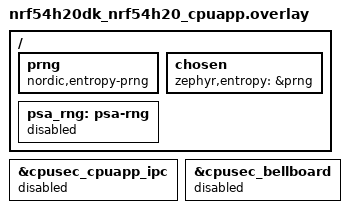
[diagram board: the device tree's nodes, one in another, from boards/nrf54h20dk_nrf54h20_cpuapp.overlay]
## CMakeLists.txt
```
#
# Copyright (c) 2022 Nordic Semiconductor ASA
#
# SPDX-License-Identifier: LicenseRef-Nordic-5-Clause
#

cmake_minimum_required(VERSION 3.20.0)

find_package(Zephyr REQUIRED HINTS $ENV{ZEPHYR_BASE})
project(nrf_wifi_shell)

if(CONFIG_NRF71_WIFI_TX_INJECTION_SUPPORT OR CONFIG_NRF71_WIFI_PROMISCUOUS_SUPPORT)
  target_include_directories(app PUBLIC ${ZEPHYR_BASE}/subsys/net/ip)
endif()

target_sources_ifdef(CONFIG_NRF70_RAW_DATA_TX app PRIVATE src/wifi_raw_tx_pkt_shell.c)
target_sources_ifdef(CONFIG_NRF71_WIFI_TX_INJECTION_SUPPORT app PRIVATE src/wifi_raw_tx_pkt_shell.c)

target_sources_ifdef(CONFIG_NRF70_PROMISC_DATA_RX app PRIVATE src/wifi_promiscuous_shell.c)
target_sources_ifdef(CONFIG_NRF71_WIFI_PROMISCUOUS_SUPPORT app PRIVATE src/wifi_promiscuous_shell.c)

target_sources(app PRIVATE src/main.c)
```

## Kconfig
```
#
# Copyright (c) 2024 Nordic Semiconductor
#
# SPDX-License-Identifier: LicenseRef-Nordic-5-Clause
#

menu "Nordic Shell sample"

if NET_BUF_FIXED_DATA_SIZE

config NET_BUF_DATA_SIZE
	default 1100

endif

# Configure variable network buffer pool sizes for TX and RX
if NET_BUF_VARIABLE_DATA_SIZE

# nRF52 and nRF54 Series targets have less memory
# so smaller pool sizes are recommended for these targets.
config NET_PKT_BUF_TX_DATA_POOL_SIZE
	default 50000 if SOC_NRF54LM20A || SOC_NRF54LM20B
	default 40000 if SOC_SERIES_NRF54H
	default 35000 if !SOC_SERIES_NRF52 && !SOC_SERIES_NRF54L && BUILD_WITH_TFM
	default 50000 if !SOC_SERIES_NRF52 && !SOC_SERIES_NRF54L

config NET_PKT_BUF_RX_DATA_POOL_SIZE
	default 20000 if SOC_NRF54LM20A || SOC_NRF54LM20B
	default 20000 if !SOC_SERIES_NRF52 && !SOC_SERIES_NRF54L

endif


source "Kconfig.zephyr"

endmenu
```

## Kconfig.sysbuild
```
#
# Copyright (c) 2024 Nordic Semiconductor ASA
#
# SPDX-License-Identifier: LicenseRef-Nordic-5-Clause
#

source "${ZEPHYR_NRF_MODULE_DIR}/samples/wifi/Kconfig.sysbuild.nrf70"

# nRF91 Series devices only support Wi-Fi through an nRF70 Series shield in scan-only mode.
choice WIFI_NRF70_OPER_MODES
	default WIFI_NRF70_SCAN_ONLY if BOARD_NRF9151DK_NRF9151_NS || \
		BOARD_NRF9160DK_NRF9160_NS || BOARD_NRF9161DK_NRF9161_NS || \
		BOARD_THINGY91X_NRF9151_NS
endchoice

source "share/sysbuild/Kconfig"
```

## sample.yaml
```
sample:
  description: Wi-Fi shell sample application
  name: Wi-Fi shell
tests:
  sample.nrf7002.shell:
    sysbuild: true
    build_only: true
    integration_platforms:
      - nrf7002dk/nrf5340/cpuapp
    platform_allow: nrf7002dk/nrf5340/cpuapp
    tags:
      - ci_build
      - sysbuild
      - ci_samples_wifi
  # Disable optional features to reduce memory usage
  sample.nrf7002.shell.disable_adv_features:
    sysbuild: true
    build_only: true
    extra_args: -DCONFIG_WIFI_NM_WPA_SUPPLICANT_ADVANCED_FEATURES=n
    integration_platforms:
      - nrf7002dk/nrf5340/cpuapp
    platform_allow: nrf7002dk/nrf5340/cpuapp
    tags:
      - ci_build
      - sysbuild
      - ci_samples_wifi
  sample.nrf7001.shell:
    sysbuild: true
    build_only: true
    integration_platforms:
      - nrf7002dk/nrf5340/cpuapp/nrf7001
    platform_allow: nrf7002dk/nrf5340/cpuapp/nrf7001
    tags:
      - ci_build
      - sysbuild
      - ci_samples_wifi
  sample.nrf7002_eks.shell:
    sysbuild: true
    build_only: true
    extra_args: SHIELD=nrf7002ek
    integration_platforms:
      - nrf5340dk/nrf5340/cpuapp
    platform_allow:
      - nrf5340dk/nrf5340/cpuapp
      - nrf52840dk/nrf52840
    tags:
      - ci_build
      - sysbuild
      - ci_samples_wifi
  sample.nrf7000_eks.shell:
    sysbuild: true
    build_only: true
    extra_args:
      - SHIELD=nrf7002ek_nrf7000
      - CONFIG_WIFI_NM_WPA_SUPPLICANT=n
      - SB_CONFIG_WIFI_NRF70_SCAN_ONLY=y
      - CONFIG_NET_CONNECTION_MANAGER=n
    integration_platforms:
      - nrf5340dk/nrf5340/cpuapp
      - nrf52840dk/nrf52840
    platform_allow:
      - nrf5340dk/nrf5340/cpuapp
      - nrf52840dk/nrf52840
    tags:
      - ci_build
      - sysbuild
      - ci_samples_wifi
  sample.nrf7001_eks.shell:
    sysbuild: true
    build_only: true
    extra_args: SHIELD=nrf7002ek_nrf7001
    integration_platforms:
      - nrf52840dk/nrf52840
    platform_allow:
      - nrf5340dk/nrf5340/cpuapp
      - nrf52840dk/nrf52840
    tags:
      - ci_build
      - sysbuild
      - ci_samples_wifi
  sample.nrf7002_eks_cpunet.shell:
    sysbuild: true
    build_only: true
    extra_args:
      - SHIELD=nrf7002ek
      - CONFIG_SOC_NRF53_CPUNET_ENABLE=y
    integration_platforms:
      - nrf5340dk/nrf5340/cpuapp
    platform_allow: nrf5340dk/nrf5340/cpuapp
    tags:
      - ci_build
      - sysbuild
      - ci_samples_wifi
  sample.nrf7000_eks_cpunet.shell:
    sysbuild: true
    build_only: true
    extra_args:
      - SHIELD=nrf7002ek_nrf7000
      - CONFIG_SOC_NRF53_CPUNET_ENABLE=y
      - CONFIG_WIFI_NM_WPA_SUPPLICANT=n
      - SB_CONFIG_WIFI_NRF70_SCAN_ONLY=y
      - CONFIG_NET_CONNECTION_MANAGER=n
    integration_platforms:
      - nrf5340dk/nrf5340/cpuapp
    platform_allow: nrf5340dk/nrf5340/cpuapp
    tags:
      - ci_build
      - sysbuild
      - ci_samples_wifi
  sample.nrf7001_eks_cpunet.shell:
    sysbuild: true
    build_only: true
    extra_args:
      - SHIELD=nrf7002ek_nrf7001
      - CONFIG_SOC_NRF53_CPUNET_ENABLE=y
    integration_platforms:
      - nrf5340dk/nrf5340/cpuapp
    platform_allow: nrf5340dk/nrf5340/cpuapp
    tags:
      - ci_build
      - sysbuild
      - ci_samples_wifi
  sample.nrf7002.shell.zperf:
    sysbuild: true
    build_only: true
    extra_args: EXTRA_CONF_FILE=overlay-zperf.conf
    integration_platforms:
      - nrf7002dk/nrf5340/cpuapp
    platform_allow: nrf7002dk/nrf5340/cpuapp
    tags:
      - ci_build
      - sysbuild
      - ci_samples_wifi
  sample.nrf7001.shell.zperf:
    sysbuild: true
    build_only: true
    extra_args: EXTRA_CONF_FILE=overlay-zperf.conf
    integration_platforms:
      - nrf7002dk/nrf5340/cpuapp/nrf7001
    platform_allow: nrf7002dk/nrf5340/cpuapp/nrf7001
    tags:
      - ci_build
      - sysbuild
      - ci_samples_wifi
  sample.nrf7002.shell.wpa_cli:
    sysbuild: true
    build_only: true
    extra_args: CONFIG_WPA_CLI=y
    integration_platforms:
      - nrf7002dk/nrf5340/cpuapp
    platform_allow: nrf7002dk/nrf5340/cpuapp
    tags:
      - ci_build
      - sysbuild
      - ci_samples_wifi
  sample.nrf7001.shell.wpa_cli:
    sysbuild: true
    build_only: true
    extra_args: CONFIG_WPA_CLI=y
    integration_platforms:
      - nrf7002dk/nrf5340/cpuapp/nrf7001
    platform_allow: nrf7002dk/nrf5340/cpuapp/nrf7001
    tags:
      - ci_build
      - sysbuild
      - ci_samples_wifi
  sample.nrf7002.shell.scan_only_7002:
    sysbuild: true
    build_only: true
    extra_args:
      - EXTRA_CONF_FILE=overlay-scan-only.conf
      - SB_CONFIG_WIFI_NRF70_SCAN_ONLY=y
    integration_platforms:
      - nrf7002dk/nrf5340/cpuapp
    platform_allow: nrf7002dk/nrf5340/cpuapp
    tags:
      - ci_build
      - sysbuild
      - ci_samples_wifi
  sample.nrf7000.shell.scan_only_91:
    sysbuild: true
    build_only: true
    extra_args:
      - EXTRA_CONF_FILE=overlay-scan-only.conf
      - SHIELD=nrf7002ek_nrf7000
      - CONFIG_TFM_PROFILE_TYPE_MINIMAL=y
      - CONFIG_WIFI_NM_WPA_SUPPLICANT=n
    integration_platforms:
      - nrf9160dk/nrf9160/ns
      - nrf9161dk/nrf9161/ns
    platform_allow:
      - nrf9160dk/nrf9160/ns
      - nrf9161dk/nrf9161/ns
      - nrf9151dk/nrf9151/ns
    tags:
      - ci_build
      - sysbuild
      - ci_samples_wifi
  sample.nrf7002.shell.scan_only_thingy91x:
    sysbuild: true
    build_only: true
    extra_args:
      - EXTRA_CONF_FILE=overlay-scan-only.conf
    platform_allow:
      - thingy91x/nrf9151/ns
    tags:
      - ci_build
      - sysbuild
      - ci_samples_wifi
  sample.nrf7002.shell.full_stack_thingy91x:
    sysbuild: true
    build_only: true
    platform_allow:
      - thingy91x/nrf5340/cpuapp
    tags:
      - ci_build
      - sysbuild
      - ci_samples_wifi
  sample.nrf7002.shell.otbr:
    sysbuild: true
    build_only: true
    extra_args:
      - EXTRA_CONF_FILE=overlay-openthread.conf
      - SB_CONFIG_NETCORE_IPC_RADIO=y
      - SB_CONFIG_NETCORE_IPC_RADIO_IEEE802154=y
    integration_platforms:
      - nrf7002dk/nrf5340/cpuapp
    platform_allow: nrf7002dk/nrf5340/cpuapp
    tags:
      - ci_build
      - sysbuild
      - ci_samples_wifi
  sample.nrf7002_ns.shell:
    sysbuild: true
    build_only: true
    platform_allow: nrf7002dk/nrf5340/cpuapp/ns
    tags:
      - sysbuild
      - ci_samples_wifi
  sample.nrf7002_eb.thingy53.shell:
    sysbuild: true
    build_only: true
    extra_args:
      - shell_SHIELD=nrf7002eb
      - CONFIG_SOC_NRF53_CPUNET_ENABLE=y
    integration_platforms:
      - thingy53/nrf5340/cpuapp
    platform_allow: thingy53/nrf5340/cpuapp
    tags:
      - ci_build
      - sysbuild
      - ci_samples_wifi
  sample.qspi.ext_flash_xip:
    sysbuild: true
    build_only: true
    extra_args:
      - shell_SHIELD=nrf7002ek
      - SB_CONFIG_WIFI_PATCHES_EXT_FLASH_XIP=y
    integration_platforms:
      - nrf5340dk/nrf5340/cpuapp
      - nrf52840dk/nrf52840
    platform_allow:
      - nrf5340dk/nrf5340/cpuapp
      - nrf52840dk/nrf52840
    tags:
      - ci_build
      - sysbuild
      - ci_samples_wifi
  sample.qspi.ext_flash_store:
    sysbuild: true
    build_only: true
    extra_args:
      - shell_SHIELD=nrf7002ek
      - shell_SNIPPET=nrf70-fw-patch-ext-flash
    integration_platforms:
      - nrf5340dk/nrf5340/cpuapp
      - nrf52840dk/nrf52840
    platform_allow:
      - nrf5340dk/nrf5340/cpuapp
      - nrf52840dk/nrf52840
    tags:
      - ci_build
      - sysbuild
      - ci_samples_wifi
  sample.spi.ext_flash_store:
    sysbuild: true
    build_only: true
    extra_args:
      - SNIPPET=nrf70-fw-patch-ext-flash
    integration_platforms:
      - nrf7002dk/nrf5340/cpuapp
    platform_allow:
      - nrf7002dk/nrf5340/cpuapp
    tags:
      - ci_build
      - sysbuild
      - ci_samples_wifi
  sample.nrf7002eb_interposer_p1.nrf7002eb.shell:
    sysbuild: true
    build_only: true
    extra_args:
      - shell_SHIELD="nrf7002eb_interposer_p1;nrf7002eb"
      - shell_SNIPPET=nrf70-wifi
    integration_platforms:
      - nrf54h20dk/nrf54h20/cpuapp
      - nrf54l15dk/nrf54l15/cpuapp
    platform_allow:
      - nrf54h20dk/nrf54h20/cpuapp
      - nrf54l15dk/nrf54l15/cpuapp
    tags:
      - ci_build
      - sysbuild
      - ci_samples_wifi
  sample.nrf7002eb_interposer_p1.nrf7002eb.shell.superset:
    sysbuild: true
    build_only: true
    extra_args:
      - shell_SHIELD="nrf7002eb_interposer_p1;nrf7002eb"
      - shell_SNIPPET=nrf70-wifi
      - EXTRA_CONF_FILE=overlay-zperf.conf
      - CONFIG_NRF70_UTIL=y
      - CONFIG_WPA_CLI=y
      - CONFIG_NET_IPV4_FRAGMENT=y
      - CONFIG_NET_IPV4_FRAGMENT_MAX_PKT=24
      - CONFIG_NRF_WIFI_DATA_HEAP_SIZE=199000
    integration_platforms:
      - nrf54h20dk/nrf54h20/cpuapp
    platform_allow:
      - nrf54h20dk/nrf54h20/cpuapp
    tags:
      - ci_build
      - sysbuild
      - ci_samples_wifi
  sample.nrf7002eb2.shell:
    sysbuild: true
    build_only: true
    extra_args:
      - shell_SHIELD="nrf7002eb2"
      - SNIPPET=nrf70-wifi
    integration_platforms:
      - nrf54l15dk/nrf54l15/cpuapp
    platform_allow:
      - nrf54l15dk/nrf54l15/cpuapp
    tags:
      - ci_build
      - sysbuild
      - ci_samples_wifi
  sample.54lm20dk.nrf7002eb2.shell:
    sysbuild: true
    build_only: true
    extra_args:
      - shell_SHIELD="nrf7002eb2"
    integration_platforms:
      - nrf54lm20dk/nrf54lm20a/cpuapp
      - nrf54lm20dk/nrf54lm20a/cpuapp/ns
      - nrf54lm20dk/nrf54lm20b/cpuapp
      - nrf54lm20dk/nrf54lm20b/cpuapp/ns
    platform_allow:
      - nrf54lm20dk/nrf54lm20a/cpuapp
      - nrf54lm20dk/nrf54lm20a/cpuapp/ns
      - nrf54lm20dk/nrf54lm20b/cpuapp
      - nrf54lm20dk/nrf54lm20b/cpuapp/ns
    tags:
      - ci_build
      - sysbuild
      - ci_samples_wifi
  # Used by QA and also acts as a memory stress test
  sample.nrf7001.superset:
    sysbuild: true
    build_only: true
    extra_args:
      - EXTRA_CONF_FILE=overlay-zperf.conf
      - CONFIG_NRF70_UTIL=y
      - CONFIG_WPA_CLI=y
      - CONFIG_NET_IPV4_FRAGMENT=y
      - CONFIG_NET_IPV4_FRAGMENT_MAX_PKT=24
    integration_platforms:
      - nrf7002dk/nrf5340/cpuapp/nrf7001
    platform_allow: nrf7002dk/nrf5340/cpuapp/nrf7001
    tags:
      - ci_build_superset
      - sysbuild
      - ci_samples_wifi
  # Used by QA and also acts as a memory stress test
  sample.nrf7001_ek.superset:
    sysbuild: true
    build_only: true
    extra_args:
      - SHIELD=nrf7002ek_nrf7001
      - EXTRA_CONF_FILE=overlay-zperf.conf
      - CONFIG_NRF70_UTIL=y
      - CONFIG_WPA_CLI=y
      - CONFIG_NET_IPV4_FRAGMENT=y
      - CONFIG_NET_IPV4_FRAGMENT_MAX_PKT=24
    integration_platforms:
      - nrf5340dk/nrf5340/cpuapp
    platform_allow: nrf5340dk/nrf5340/cpuapp
    tags:
      - ci_build_superset
      - sysbuild
      - ci_samples_wifi
  # Used by QA and also acts as a memory stress test
  sample.nrf7002.superset:
    sysbuild: true
    build_only: true
    extra_args:
      - EXTRA_CONF_FILE=overlay-zperf.conf
      - CONFIG_NRF70_UTIL=y
      - CONFIG_WPA_CLI=y
      - CONFIG_NET_IPV4_FRAGMENT=y
      - CONFIG_NET_IPV4_FRAGMENT_MAX_PKT=24
    integration_platforms:
      - nrf7002dk/nrf5340/cpuapp
    platform_allow: nrf7002dk/nrf5340/cpuapp
    tags:
      - ci_build_superset
      - sysbuild
      - ci_samples_wifi
  # Used by QA and also acts as a memory stress test
  sample.nrf7002_ek.superset:
    sysbuild: true
    build_only: true
    extra_args:
      - SHIELD=nrf7002ek
      - EXTRA_CONF_FILE=overlay-zperf.conf
      - CONFIG_NRF70_UTIL=y
      - CONFIG_WPA_CLI=y
      - CONFIG_NET_IPV4_FRAGMENT=y
      - CONFIG_NET_IPV4_FRAGMENT_MAX_PKT=24
    integration_platforms:
      - nrf5340dk/nrf5340/cpuapp
    platform_allow: nrf5340dk/nrf5340/cpuapp
    tags:
      - ci_build_superset
      - sysbuild
      - ci_samples_wifi
  sample.nrf7002.superset.debug:
    sysbuild: true
    build_only: true
    extra_args:
      - shell_SNIPPET="nrf70-driver-verbose-debug;wpa-supplicant-debug"
      - EXTRA_CONF_FILE=overlay-zperf.conf
      - CONFIG_NRF70_UTIL=y
      - CONFIG_WPA_CLI=y
      - CONFIG_NET_IPV4_FRAGMENT=y
      - CONFIG_NET_IPV4_FRAGMENT_MAX_PKT=24
    integration_platforms:
      - nrf7002dk/nrf5340/cpuapp
    platform_allow: nrf7002dk/nrf5340/cpuapp
    tags:
      - ci_build_superset
      - sysbuild
      - ci_samples_wifi
  sample.nrf7002.enterprise_mode:
    sysbuild: true
    build_only: true
    extra_args: shell_SNIPPET=nordic-wifi-enterprise
    integration_platforms:
      - nrf7002dk/nrf5340/cpuapp
    platform_allow: nrf7002dk/nrf5340/cpuapp
    tags:
      - ci_build
      - sysbuild
      - ci_samples_wifi
  sample.nrf7002.ap:
    sysbuild: true
    build_only: true
    extra_args: shell_SNIPPET=wifi-sap
    integration_platforms:
      - nrf7002dk/nrf5340/cpuapp
    platform_allow: nrf7002dk/nrf5340/cpuapp
    tags:
      - ci_build
      - sysbuild
      - ci_samples_wifi
  sample.nrf7002.with_overlay_raw_tx_packet:
    sysbuild: true
    build_only: true
    extra_args:
      - shell_SNIPPET=wifi-raw-tx
      - SB_CONFIG_WIFI_NRF70_SYSTEM_WITH_RAW_MODES=y
    integration_platforms:
      - nrf7002dk/nrf5340/cpuapp
    platform_allow: nrf7002dk/nrf5340/cpuapp
    tags:
      - ci_build
      - sysbuild
      - ci_samples_wifi
  sample.nrf7002.with_overlay_monitor:
    sysbuild: true
    build_only: true
    extra_args:
      - shell_SNIPPET=wifi-monitor-mode
      - SB_CONFIG_WIFI_NRF70_SYSTEM_WITH_RAW_MODES=y
    integration_platforms:
      - nrf7002dk/nrf5340/cpuapp
    platform_allow: nrf7002dk/nrf5340/cpuapp
    tags:
      - ci_build
      - sysbuild
      - ci_samples_wifi
  sample.nrf7002.promiscuous_mode:
    sysbuild: true
    build_only: true
    extra_args:
      - shell_SNIPPET=wifi-promiscuous-mode
      - SB_CONFIG_WIFI_NRF70_SYSTEM_WITH_RAW_MODES=y
    integration_platforms:
      - nrf7002dk/nrf5340/cpuapp
    platform_allow: nrf7002dk/nrf5340/cpuapp
    tags:
      - ci_build
      - sysbuild
      - ci_samples_wifi
  sample.nrf7001.promiscuous_mode_7001:
    sysbuild: true
    build_only: true
    extra_args:
      - shell_SNIPPET=wifi-promiscuous-mode
      - SB_CONFIG_WIFI_NRF70_SYSTEM_WITH_RAW_MODES=y
    integration_platforms:
      - nrf7002dk/nrf5340/cpuapp/nrf7001
    platform_allow: nrf7002dk/nrf5340/cpuapp/nrf7001
    tags:
      - ci_build
      - sysbuild
      - ci_samples_wifi
  sample.nrf54l15.softap.superset:
    sysbuild: true
    build_only: true
    extra_args:
      - softap_SHIELD="nrf7002eb_interposer_p1;nrf7002eb"
      - softap_SNIPPET=nrf70-wifi
      - CONFIG_HEAP_MEM_POOL_IGNORE_MIN=n
    integration_platforms:
      - nrf54l15dk/nrf54l15/cpuapp
    platform_allow:
      - nrf54l15dk/nrf54l15/cpuapp
    tags:
      - ci_build
      - sysbuild
      - ci_samples_wifi
  sample.nrf7120.shell:
    sysbuild: true
    build_only: true
    integration_platforms:
      - nrf7120dk/nrf7120/cpuapp
      - nrf7120dk/nrf7120/cpuapp/ns
    platform_allow:
      - nrf7120dk/nrf7120/cpuapp
      - nrf7120dk/nrf7120/cpuapp/ns
    tags:
      - ci_build
      - sysbuild
      - ci_samples_nrf71_wifi
  sample.nrf7120.shell.ap:
    sysbuild: true
    build_only: true
    extra_args:
      - shell_SNIPPET=wifi-sap
    integration_platforms:
      - nrf7120dk/nrf7120/cpuapp
    platform_allow:
      - nrf7120dk/nrf7120/cpuapp
    tags:
      - ci_build
      - sysbuild
      - ci_samples_nrf71_wifi
  sample.nrf7120.shell.monitor:
    sysbuild: true
    build_only: true
    extra_args:
      - shell_SNIPPET=wifi-monitor-mode
    integration_platforms:
      - nrf7120dk/nrf7120/cpuapp
    platform_allow:
      - nrf7120dk/nrf7120/cpuapp
    tags:
      - ci_build
      - sysbuild
      - ci_samples_nrf71_wifi
  sample.nrf7120.shell.promiscuous:
    sysbuild: true
    build_only: true
    extra_args:
      - shell_SNIPPET=wifi-promiscuous-mode
    integration_platforms:
      - nrf7120dk/nrf7120/cpuapp
    platform_allow:
      - nrf7120dk/nrf7120/cpuapp
    tags:
      - ci_build
      - sysbuild
      - ci_samples_nrf71_wifi
  sample.nrf7120.shell.raw_tx:
    sysbuild: true
    build_only: true
    extra_args:
      - shell_SNIPPET=wifi-raw-tx
    integration_platforms:
      - nrf7120dk/nrf7120/cpuapp
    platform_allow:
      - nrf7120dk/nrf7120/cpuapp
    tags:
      - ci_build
      - sysbuild
      - ci_samples_nrf71_wifi
  sample.nrf7120.shell.p2p:
    sysbuild: true
    build_only: true
    extra_args:
      - shell_SNIPPET:STRING=wifi-p2p
      - CONFIG_NET_DHCPV4_SERVER=y
    platform_allow:
      - nrf7120dk/nrf7120/cpuapp
    # Fails to link: Wi-Fi patch region overlaps Zephyr build on nrf7120dk
    platform_exclude:
      - nrf7120dk/nrf7120/cpuapp
    tags:
      - ci_build
      - sysbuild
      - ci_samples_nrf71_wifi
  sample.nrf7002.shell.wpa3_psa:
    build_only: true
    extra_args:
      - CONFIG_HOSTAP_CRYPTO_WPA3_PSA=y
      - CONFIG_HOSTAP_CRYPTO_ALT_PSA=y
      # HostAP crypto still uses the deprecated legacy MbedTLS symbols.
      - CONFIG_DEPRECATED_KCONFIGS_AS_ERRORS=n
    integration_platforms:
      - nrf7002dk/nrf5340/cpuapp
    platform_allow: nrf7002dk/nrf5340/cpuapp
    tags:
      - ci_build
      - sysbuild
      - ci_samples_wifi
  sample.nrf7120.shell.zperf:
    sysbuild: true
    build_only: true
    extra_args:
      - EXTRA_CONF_FILE=nrf71-zperf.conf
    integration_platforms:
      - nrf7120dk/nrf7120/cpuapp
    platform_allow: nrf7120dk/nrf7120/cpuapp
    tags:
      - ci_build
      - sysbuild
      - ci_samples_wifi
  sample.nrf7120.shell.enterprise:
    sysbuild: true
    build_only: true
    extra_args:
      - shell_SNIPPET=nordic-wifi-enterprise
    integration_platforms:
      - nrf7120dk/nrf7120/cpuapp
    platform_allow:
      - nrf7120dk/nrf7120/cpuapp
    tags:
      - ci_build
      - sysbuild
      - ci_samples_nrf71_wifi
  sample.nrf7120.superset:
    sysbuild: true
    build_only: true
    extra_args:
      - EXTRA_CONF_FILE=nrf71-zperf.conf
      - CONFIG_WPA_CLI=y
      - CONFIG_NET_IPV4_FRAGMENT=y
      - CONFIG_NET_IPV4_FRAGMENT_MAX_PKT=24
    integration_platforms:
      - nrf7120dk/nrf7120/cpuapp
    platform_allow: nrf7120dk/nrf7120/cpuapp
    tags:
      - ci_build_superset
      - sysbuild
      - ci_samples_nrf71_wifi
```

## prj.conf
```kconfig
#
# Copyright (c) 2022 Nordic Semiconductor ASA
#
# SPDX-License-Identifier: LicenseRef-Nordic-5-Clause
#
CONFIG_WIFI=y

# WPA supplicant
CONFIG_WIFI_NM_WPA_SUPPLICANT=y
CONFIG_NET_L2_WIFI_SHELL=y

# Networking
CONFIG_NETWORKING=y
CONFIG_NET_SOCKETS=y
CONFIG_NET_LOG=y
CONFIG_NET_IPV6=y
CONFIG_NET_IPV4=y
CONFIG_NET_UDP=y
CONFIG_NET_TCP=y
CONFIG_NET_DHCPV4=y
CONFIG_DNS_RESOLVER=y

CONFIG_NET_STATISTICS=y
CONFIG_NET_STATISTICS_WIFI=y
CONFIG_NET_STATISTICS_USER_API=y

CONFIG_NET_PKT_RX_COUNT=8
CONFIG_NET_PKT_TX_COUNT=8

# Below section is the primary contributor to SRAM and is currently
# tuned for performance, but this will be revisited in the future.
CONFIG_NET_BUF_RX_COUNT=16
CONFIG_NET_BUF_TX_COUNT=16
CONFIG_NET_TC_TX_COUNT=1

CONFIG_NET_IF_UNICAST_IPV6_ADDR_COUNT=4
CONFIG_NET_IF_MCAST_IPV6_ADDR_COUNT=5
CONFIG_NET_MAX_CONTEXTS=5
CONFIG_NET_CONTEXT_SYNC_RECV=y

CONFIG_INIT_STACKS=y

CONFIG_NET_L2_ETHERNET=y
CONFIG_NET_SHELL=y

# Zephyr NET Connection Manager Connectivity layer.
CONFIG_NET_CONNECTION_MANAGER=y
CONFIG_L2_WIFI_CONNECTIVITY=y
CONFIG_L2_WIFI_CONNECTIVITY_AUTO_CONNECT=y
CONFIG_L2_WIFI_CONNECTIVITY_AUTO_DOWN=n

# Memories
CONFIG_MAIN_STACK_SIZE=4800
CONFIG_SHELL_STACK_SIZE=5400

CONFIG_NET_TX_STACK_SIZE=4096
CONFIG_NET_RX_STACK_SIZE=4096
CONFIG_NET_CONNECTION_MANAGER_MONITOR_STACK_SIZE=5000

# Debugging
CONFIG_STACK_SENTINEL=y
CONFIG_DEBUG_COREDUMP=y
CONFIG_DEBUG_COREDUMP_BACKEND_LOGGING=y
CONFIG_DEBUG_COREDUMP_MEMORY_DUMP_MIN=y
CONFIG_SHELL_CMDS_RESIZE=n
#CONFIG_DEBUG=y
CONFIG_WIFI_NM_WPA_SUPPLICANT_LOG_LEVEL_INF=y

# Kernel options
CONFIG_ENTROPY_GENERATOR=y
CONFIG_REBOOT=y

# Logging
CONFIG_LOG=y
CONFIG_PRINTK=y
CONFIG_SHELL=y
CONFIG_SHELL_GETOPT=y
CONFIG_DEVICE_SHELL=y
CONFIG_POSIX_TIMERS=y
CONFIG_DATE_SHELL=y
CONFIG_NET_CONFIG_AUTO_INIT=n
CONFIG_POSIX_API=y

CONFIG_WIFI_CREDENTIALS=y
CONFIG_FLASH=y
CONFIG_FLASH_PAGE_LAYOUT=y
CONFIG_FLASH_MAP=y
CONFIG_NVS=y
CONFIG_SETTINGS=y
CONFIG_SETTINGS_NVS=y

# printing of scan results puts pressure on queues in new locking
# design in net_mgmt. So, use a higher timeout for a crowded
# environment.
CONFIG_NET_MGMT_EVENT_QUEUE_TIMEOUT=5000
CONFIG_ZVFS_POLL_MAX=12
CONFIG_NET_MGMT_EVENT_QUEUE_SIZE=16
```

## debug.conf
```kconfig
CONFIG_SHELL=y
CONFIG_SHELL_STACK_SIZE=4096
CONFIG_NET_SHELL=y
CONFIG_SHELL_GETOPT=y
CONFIG_SHELL_CMDS_RESIZE=n
CONFIG_NRF700X_UTIL=y
CONFIG_NET_L2_WIFI_SHELL=y
CONFIG_NET_STATISTICS=y
CONFIG_NET_STATISTICS_WIFI=y
CONFIG_NET_STATISTICS_USER_API=y
CONFIG_SYS_HEAP_RUNTIME_STATS=y
CONFIG_WPA_SUPP_LOG_LEVEL_DBG=y
```

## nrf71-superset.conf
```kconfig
#
# Copyright (c) 2026 Nordic Semiconductor ASA
#
# SPDX-License-Identifier: LicenseRef-Nordic-5-Clause
#
# nRF7120 shell superset: all Wi-Fi modes, zperf, enterprise, and optional
# networking features enabled for QA / memory stress testing.

CONFIG_WIFI_NRF71=y

# All Wi-Fi operating modes (single VIF; runtime mode selection via shell)
CONFIG_NRF71_STA_MODE=y
CONFIG_NRF71_AP_MODE=y
CONFIG_WIFI_NM_WPA_SUPPLICANT_AP=y
CONFIG_NRF71_P2P_MODE=y
CONFIG_WIFI_NM_WPA_SUPPLICANT_P2P=y
CONFIG_NRF71_RAW_DATA_RX=y
CONFIG_NRF71_PROMISC_DATA_RX=y
CONFIG_NRF71_RAW_DATA_TX=y
CONFIG_NRF71_SYSTEM_WITH_RAW_MODES=y
CONFIG_NET_SOCKETS_PACKET=y
CONFIG_NET_DHCPV4_SERVER=y

# Zperf
CONFIG_NET_ZPERF=y
CONFIG_NET_ZPERF_SERVER=y
CONFIG_ZVFS_POLL_MAX=20
CONFIG_NET_CONFIG_SETTINGS=y
CONFIG_NET_CONFIG_INIT_TIMEOUT=0

# Enterprise
CONFIG_WIFI_NM_WPA_SUPPLICANT_CRYPTO_ENTERPRISE=y
CONFIG_NET_BUF_VARIABLE_DATA_SIZE=y
CONFIG_MBEDTLS_ENABLE_HEAP=y
CONFIG_MBEDTLS_HEAP_SIZE=70000
CONFIG_TLS_CREDENTIALS_SHELL=y
CONFIG_BASE64=y
CONFIG_TLS_CREDENTIALS=y
CONFIG_TLS_CREDENTIALS_SHELL_CRED_BUF_SIZE=8192
CONFIG_TLS_MAX_CREDENTIALS_NUMBER=6
CONFIG_HEAP_MEM_POOL_ADD_SIZE_TLS_CRED_SHELL=9000
CONFIG_WIFI_CREDENTIALS_RUNTIME_CERTIFICATES=y
CONFIG_WIFI_SHELL_RUNTIME_CERTIFICATES=y
CONFIG_WIFI_NM_WPA_SUPPLICANT_THREAD_STACK_SIZE=12000

# Superset extras
CONFIG_WPA_CLI=y
CONFIG_NET_IPV4_FRAGMENT=y
CONFIG_NET_IPV4_FRAGMENT_MAX_PKT=24
CONFIG_WIFI_NM_WPA_SUPPLICANT_WEP=y
CONFIG_NET_ARP_GRATUITOUS_TRANSMISSION=y
CONFIG_NET_ARP_GRATUITOUS_INTERVAL=30

# Driver / shell utilities
CONFIG_NRF71_UTIL=y

# Performance tuning
CONFIG_PICOLIBC_USE_MODULE=y
CONFIG_SPEED_OPTIMIZATIONS=y
CONFIG_CACHE_MANAGEMENT=y
CONFIG_MAIN_STACK_SIZE=5200
CONFIG_SHELL_STACK_SIZE=5200
CONFIG_NET_MGMT_EVENT_STACK_SIZE=4600
CONFIG_NET_PKT_RX_COUNT=28
CONFIG_NET_PKT_TX_COUNT=27
CONFIG_NET_BUF_RX_COUNT=28
CONFIG_NET_BUF_TX_COUNT=54
CONFIG_NRF_WIFI_LOW_POWER=n
CONFIG_NRF71_RX_NUM_BUFS=48
CONFIG_NRF71_MAX_TX_AGGREGATION=12
CONFIG_NRF_WIFI_CTRL_HEAP_SIZE=25000
CONFIG_NRF_WIFI_DATA_HEAP_SIZE=199856
CONFIG_HEAP_MEM_POOL_SIZE=100000
CONFIG_NET_CONNECTION_MANAGER=n
CONFIG_LOG_RATELIMIT=n
CONFIG_POSIX_MULTI_PROCESS=n
```

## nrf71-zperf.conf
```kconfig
# nRF71 zperf overlay: build shell with EXTRA_CONF_FILE=nrf71-zperf.conf
# TCP STA upload: zperf tcp upload -n -a <host> 5001 10 1400
# TCP STA download: zperf tcp download 5001 (peer sends, e.g. iperf -c)
# UDP flood: zperf udp upload <host> 5001 10 1K <high rate e.g. 800M>
CONFIG_NET_ZPERF=y
CONFIG_NET_ZPERF_SERVER=y
# Zperf TCP=6, UDP=2, Others=1
CONFIG_ZVFS_POLL_MAX=20
# Sockets: select + poll take up more stack
CONFIG_MAIN_STACK_SIZE=5200
CONFIG_SHELL_STACK_SIZE=5200
CONFIG_NET_MGMT_EVENT_STACK_SIZE=4600

# Optimized networking settings for performance
CONFIG_NET_PKT_RX_COUNT=40
CONFIG_NET_PKT_TX_COUNT=40
CONFIG_NET_BUF_RX_COUNT=40
CONFIG_NET_BUF_TX_COUNT=80
CONFIG_NET_PKT_BUF_TX_DATA_POOL_SIZE=90000
CONFIG_NET_TCP_MAX_SEND_WINDOW_SIZE=32768
CONFIG_NET_CONTEXT_SNDBUF=y
# Only for async zperf
CONFIG_ZPERF_WORK_Q_THREAD_PRIORITY=5
CONFIG_NRF71_WIFI_MAX_TX_TOKENS=12
CONFIG_HEAP_MEM_POOL_SIZE=40144
CONFIG_NRF71_WIFI_DATA_HEAP_SIZE=250000
CONFIG_NRF70_QSPI_LOW_POWER=n
# To enable optimization configuration options
CONFIG_PICOLIBC_USE_MODULE=y
CONFIG_SPEED_OPTIMIZATIONS=y
CONFIG_CACHE_MANAGEMENT=y

# Necessary for zperf_tcp_receiver.c
CONFIG_NET_CONFIG_SETTINGS=y
CONFIG_NET_CONFIG_INIT_TIMEOUT=0

# Zephyr NET Connection Manager Connectivity layer.
CONFIG_NET_CONNECTION_MANAGER=n

# Consumes more memory
CONFIG_WIFI_CREDENTIALS=n
CONFIG_FLASH=n
CONFIG_NVS=n
CONFIG_SETTINGS=n
CONFIG_NRF71_WIFI_UTIL_SHELL=y
CONFIG_NRF71_WIFI_DEBUG_SHELL=y
CONFIG_SYS_HEAP_RUNTIME_STATS=y

# Disable rate limiting to avoid log flooding (default is drop)
CONFIG_LOG_RATELIMIT=n

# Disabled to avoid pulling in CONFIG_THREAD_RUNTIME_STATS, whose
# per-context-switch overhead reduces throughput.
CONFIG_POSIX_MULTI_PROCESS=n
CONFIG_THREAD_MONITOR=n
CONFIG_TIMESLICING=n
CONFIG_NRF71_WIFI_MAX_TX_AGGREGATION=7
CONFIG_NRF71_WIFI_MAX_TX_PENDING_QLEN=36
CONFIG_NET_ZPERF_MAX_PACKET_SIZE=1600

# Receive path (TCP download / zperf tcp download)
CONFIG_NET_PKT_BUF_RX_DATA_POOL_SIZE=60000
CONFIG_NET_TCP_MAX_RECV_WINDOW_SIZE=32768
CONFIG_NET_CONTEXT_RCVBUF=y
CONFIG_NET_ZPERF_TCP_RECEIVER_BUF_SIZE=2048
CONFIG_NRF71_WIFI_RX_NUM_BUFS=24
```

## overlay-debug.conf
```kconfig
CONFIG_SHELL=y
CONFIG_SHELL_STACK_SIZE=5200
CONFIG_NET_SHELL=y
CONFIG_SHELL_GETOPT=y
CONFIG_SHELL_CMDS_RESIZE=n
CONFIG_NRF700X_UTIL=y
CONFIG_NET_L2_WIFI_SHELL=y
CONFIG_NET_STATISTICS=y
CONFIG_NET_STATISTICS_WIFI=y
CONFIG_NET_STATISTICS_USER_API=y
CONFIG_SYS_HEAP_RUNTIME_STATS=y
CONFIG_WPA_SUPP_LOG_LEVEL_DBG=y
```

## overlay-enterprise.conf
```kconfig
CONFIG_WIFI_NM_WPA_SUPPLICANT_CRYPTO_ENTERPRISE=y
# EAP frames are ~1100 bytes, so, for efficiency, we set the data size to 1100
CONFIG_NET_BUF_DATA_SIZE=1100
# Use variable data size to reduce memory usage for small data packets
CONFIG_NET_BUF_VARIABLE_DATA_SIZE=y
# For TLS and X.509 processing MbedTLS needs large heap size and using separate heap
# for MbedTLS gives us more control over the heap size.
CONFIG_MBEDTLS_ENABLE_HEAP=y
CONFIG_MBEDTLS_HEAP_SIZE=70000
```

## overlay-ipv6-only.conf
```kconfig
#
# Copyright (c) 2022 Nordic Semiconductor ASA
#
# SPDX-License-Identifier: LicenseRef-Nordic-5-Clause
#

# Configuration for IPv6 and UDP-only build variant of the shell sample.
# It relies on Router Advertisements rather than DHCP or static configuration.

CONFIG_NET_IPV4=n
CONFIG_NET_DHCPV4=n
CONFIG_NET_CONFIG_SETTINGS=n
CONFIG_NET_CONFIG_MY_IPV4_ADDR=""
CONFIG_NET_CONFIG_PEER_IPV4_ADDR=""
CONFIG_NET_CONFIG_MY_IPV6_ADDR=""
CONFIG_NET_CONFIG_PEER_IPV6_ADDR=""
CONFIG_NET_TCP=n

CONFIG_NET_STATISTICS_IPV6=y
CONFIG_NET_IPV6_ND=y
CONFIG_NET_IPV6_NBR_CACHE=y
```

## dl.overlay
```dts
CONFIG_NRF_WIFI_FEAT_KEEPALIVE=y
CONFIG_NRF_WIFI_DYNAMIC_BANDWIDTH_SIGNALLING=y
CONFIG_NRF_WIFI_RPU_MIN_TIME_TO_ENTER_SLEEP_MS=5000
CONFIG_NRF_WIFI_KEEPALIVE_PERIOD_S=30
CONFIG_NRF_WIFI_PS_EXIT_EVERY_TIM=y
```

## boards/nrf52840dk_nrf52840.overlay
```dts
/*
 * Copyright (c) 2022 Nordic Semiconductor ASA
 *
 * SPDX-License-Identifier: LicenseRef-Nordic-5-Clause
 */

/* Disabled because of a conflict on P1.08 - Arduino pin D7 (host-irq-gpios
 * in nrf7002ek).
 */
&spi1 {
	status = "disabled";
};

/* Disabled because of conflicts on P1.01 and P1.02 - Arduino pins D0 and D1
 * (iovdd-ctrl-gpios and bucken-gpios in nrf7002ek, respectively).
 */
&uart1 {
	status = "disabled";
};
```

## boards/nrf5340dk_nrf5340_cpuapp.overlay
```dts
/delete-node/ &boot_partition;
/delete-node/ &slot0_partition;
/delete-node/ &slot1_partition;
/delete-node/ &storage_partition;

&flash0 {
	partitions {
		slot0_partition: partition@0 {
			compatible = "zephyr,mapped-partition";
			label = "image-0";
			reg = <0x0 0xfc000>;
		};

		storage_partition: partition@fc000 {
			compatible = "zephyr,mapped-partition";
			label = "storage";
			reg = <0xfc000 0x2000>;
		};
	};
};
```

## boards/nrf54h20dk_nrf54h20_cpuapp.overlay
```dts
/* Copyright (c) 2024 Nordic Semiconductor ASA
 *
 * SPDX-License-Identifier: LicenseRef-Nordic-5-Clause
 */

/ {
	prng: prng {
		compatible = "nordic,entropy-prng";
		status = "okay";
	};

	chosen {
		zephyr,entropy = &prng;
	};

	psa_rng: psa-rng {
		status = "disabled";
	};
};


&cpusec_cpuapp_ipc {
	status = "disabled";
};

&cpusec_bellboard {
	status = "disabled";
};
```

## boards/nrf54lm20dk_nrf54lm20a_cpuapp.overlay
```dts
/delete-node/ &boot_partition;
/delete-node/ &slot0_partition;
/delete-node/ &slot1_partition;
/delete-node/ &storage_partition;

&cpuapp_rram {
	partitions {
		slot0_partition: partition@0 {
			compatible = "zephyr,mapped-partition";
			label = "image-0";
			reg = <0x0 0x1fb000>;
		};

		storage_partition: partition@1fb000 {
			compatible = "zephyr,mapped-partition";
			label = "storage";
			reg = <0x1fb000 0x2000>;
		};
	};
};
```

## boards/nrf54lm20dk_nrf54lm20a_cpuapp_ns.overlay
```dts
/*
 * Copyright (c) 2026 Nordic Semiconductor ASA
 *
 * SPDX-License-Identifier: LicenseRef-Nordic-5-Clause
 *
 * Reduce TF-M secure SRAM from 256 kB to 96 kB so the NS application
 * has enough RAM for the Wi-Fi shell workload.
 *
 * TF-M RAM usage on nRF54LM20A is ~50 kB; 96 kB gives comfortable headroom.
 * The NRF SDK reads S_DATA_SIZE / NS_DATA_SIZE directly from these DTS nodes.
 *
 * Total usable SRAM: 508 kB (0x7f000).
 *   sram0_s  (TF-M secure): 0x00000 .. 0x17fff  (96 kB)
 *   sram0_ns (NS app):      0x18000 .. 0x7efff  (412 kB)
 */

&sram0_s {
	reg = <0x0 DT_SIZE_K(96)>;
	ranges = <0x0 0x0 DT_SIZE_K(96)>;
};

&sram0_ns {
	reg = <DT_SIZE_K(96) DT_SIZE_K(412)>;
	ranges = <0x0 DT_SIZE_K(96) DT_SIZE_K(412)>;
};
```

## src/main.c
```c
/*
 * Copyright (c) 2022 Nordic Semiconductor ASA
 *
 * SPDX-License-Identifier: LicenseRef-Nordic-5-Clause
 */

/** @file
 * @brief WiFi shell sample main function
 */

#include <zephyr/sys/printk.h>
#include <zephyr/kernel.h>
#include <zephyr/device.h>
#include <zephyr/net/net_config.h>
#if defined(CONFIG_NRFX_CLOCK_HFCLK) && defined(CLOCK_FEATURE_HFCLK_DIVIDE_PRESENT)
#include <zephyr/drivers/clock_control/nrf_clock_control.h>

#define HFCLK_REQUESTED_FREQUENCY MHZ(128)
#endif

#if defined(CONFIG_USB_DEVICE_STACK) && !defined(CONFIG_BOARD_THINGY91X_NRF5340_CPUAPP)
#define USES_USB_ETH 1
#else
#define USES_USB_ETH 0
#endif

#if USES_USB_ETH
#include <zephyr/usb/usb_device.h>
#endif

#if USES_USB_ETH || defined(CONFIG_SLIP)
static struct in_addr addr = { { { 192, 0, 2, 1 } } };
static struct in_addr mask = { { { 255, 255, 255, 0 } } };
#endif /* CONFIG_USB_DEVICE_STACK || CONFIG_SLIP */

#if USES_USB_ETH
int init_usb(void)
{
	int ret;

	ret = usb_enable(NULL);
	if (ret != 0) {
		printk("Cannot enable USB (%d)", ret);
		return ret;
	}

	return 0;
}
#endif


int main(void)
{
#if defined(CONFIG_NRFX_CLOCK_HFCLK) && defined(CLOCK_FEATURE_HFCLK_DIVIDE_PRESENT)
	clock_control_set_rate(DEVICE_DT_GET_ONE(nordic_nrf_clock_hfclk), NULL,
			       (clock_control_subsys_rate_t)HFCLK_REQUESTED_FREQUENCY);
#endif
	printk("Starting %s with CPU frequency: %d MHz\n", CONFIG_BOARD, SystemCoreClock/MHZ(1));

#if USES_USB_ETH
	init_usb();

	/* Redirect static IP address to netusb*/
	const struct device *usb_dev = device_get_binding("eth_netusb");
	struct net_if *iface = net_if_lookup_by_dev(usb_dev);

	if (!iface) {
		printk("Cannot find network interface: %s", "eth_netusb");
		return -1;
	}

	net_if_ipv4_addr_add(iface, &addr, NET_ADDR_MANUAL, 0);
	net_if_ipv4_set_netmask_by_addr(iface, &addr, &mask);
#endif

#ifdef CONFIG_SLIP
	const struct device *slip_dev = device_get_binding(CONFIG_SLIP_DRV_NAME);
	struct net_if *slip_iface = net_if_lookup_by_dev(slip_dev);

	if (!slip_iface) {
		printk("Cannot find network interface: %s", CONFIG_SLIP_DRV_NAME);
		return -1;
	}

	net_if_ipv4_addr_add(slip_iface, &addr, NET_ADDR_MANUAL, 0);
	net_if_ipv4_set_netmask_by_addr(slip_iface, &addr, &mask);
#endif /* CONFIG_SLIP */

#ifdef CONFIG_NET_CONFIG_SETTINGS
	/* Without this, DHCPv4 starts on first interface and if that is not Wi-Fi or
	 * only supports IPv6, then its an issue. (E.g., OpenThread)
	 *
	 * So, we start DHCPv4 on Wi-Fi interface always, independent of the ordering.
	 */
	const struct device *dev = DEVICE_DT_GET(DT_CHOSEN(zephyr_wifi));
	struct net_if *wifi_iface = net_if_lookup_by_dev(dev);

	/* As both are Ethernet, we need to set specific interface*/
	net_if_set_default(wifi_iface);

	net_config_init_app(dev, "Initializing network");
#endif

	return 0;
}
```

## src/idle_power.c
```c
/*
 * Copyright (c) 2026 Nordic Semiconductor ASA
 *
 * SPDX-License-Identifier: LicenseRef-Nordic-5-Clause
 */

#include <zephyr/kernel.h>
#include <zephyr/device.h>
#include <zephyr/drivers/gpio.h>
#include <zephyr/sys/printk.h>

#include "idle_power.h"

#ifdef CONFIG_NRF7120_IDLE_DIAGNOSTICS

#include <hal/nrf_power.h>
#include <hal/nrf_memconf.h>
#include <hal/nrf_grtc.h>
#include <hal/nrf_lfxo.h>

/* GPIO configuration for idle phase marker on P0.00 */
static const struct gpio_dt_spec idle_marker = GPIO_DT_SPEC_GET_OR(
	DT_ALIAS(idle_phase), gpios, {0});

int idle_power_init(void)
{
	int ret = 0;

	if (gpio_is_ready_dt(&idle_marker)) {
		ret = gpio_pin_configure_dt(&idle_marker, GPIO_OUTPUT_HIGH);
		if (ret < 0) {
			printk("Error configuring idle marker GPIO: %d\n", ret);
			return ret;
		}
	}

	return 0;
}

void idle_power_print_snapshot(const char *phase)
{
	printk("\n%s: Power State Snapshot\n", phase);
	printk("  CONSTLATSTAT=0x%08x SYSCOUNTER_ACTIVE=0x%08x\n",
	       NRF_POWER->CONSTLATSTAT,
	       NRF_GRTC->SYSCOUNTER[0].ACTIVE);

	printk("  MEMCONF0: CONTROL=0x%08x RET=0x%08x RET2=0x%08x\n",
	       NRF_MEMCONF->POWER[0].CONTROL,
	       NRF_MEMCONF->POWER[0].RET,
	       NRF_MEMCONF->POWER[0].RET2);

	printk("  MEMCONF1: CONTROL=0x%08x RET=0x%08x RET2=0x%08x\n",
	       NRF_MEMCONF->POWER[1].CONTROL,
	       NRF_MEMCONF->POWER[1].RET,
	       NRF_MEMCONF->POWER[1].RET2);

	printk("  GRTC_MODE=0x%08x LFXO_STATUS=0x%08x LFXO_MODE=0x%08x\n",
	       NRF_GRTC->MODE,
	       NRF_LFXO->STATUS,
	       NRF_LFXO->MODE);
}

#else

int idle_power_init(void)
{
	return 0;
}

void idle_power_print_snapshot(const char *phase)
{
	ARG_UNUSED(phase);
}

#endif
```

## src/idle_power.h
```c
/*
 * Copyright (c) 2026 Nordic Semiconductor ASA
 *
 * SPDX-License-Identifier: LicenseRef-Nordic-5-Clause
 */

#ifndef WIFI_SHELL_IDLE_POWER_H
#define WIFI_SHELL_IDLE_POWER_H

#include <zephyr/kernel.h>

#ifdef CONFIG_NRF7120_IDLE_DIAGNOSTICS

/**
 * @brief Initialize idle power monitoring
 *
 * Sets up GPIO markers and diagnostic output for power measurements.
 * This function should be called early in main() after basic initialization.
 *
 * @return 0 on success, negative error code on failure
 */
int idle_power_init(void);

/**
 * @brief Print power domain and regulator state
 *
 * Outputs diagnostic information about current power domains and regulators.
 * Useful for before/after snapshots when entering/exiting idle.
 *
 * @param phase String label for this power state ("idle", "active", etc.)
 */
void idle_power_print_snapshot(const char *phase);

#else

static inline int idle_power_init(void)
{
	return 0;
}

static inline void idle_power_print_snapshot(const char *phase)
{
	ARG_UNUSED(phase);
}

#endif

#endif /* WIFI_SHELL_IDLE_POWER_H */
```

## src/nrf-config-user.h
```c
/*
 * Copyright (c) 2021 Nordic Semiconductor
 *
 * SPDX-License-Identifier: LicenseRef-Nordic-5-Clause
 *
 */

/* This file is intentionally empty.*/
```

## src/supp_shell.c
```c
/*
 * Copyright (c) 2022 Nordic Semiconductor ASA
 *
 * SPDX-License-Identifier: LicenseRef-Nordic-5-Clause
 */

/* @file
 * @brief WPA supplicant shell module
 */

#include <zephyr.h>
#include <stdio.h>
#include <stdlib.h>
#include <shell/shell.h>
#include <init.h>
#include <ctype.h>

#include <net/net_if.h>
#include <net/wifi_mgmt.h>
#include <net/net_event.h>
#include "common.h"
#include "zephyr_fmac_main.h"
#ifdef CONFIG_WPA_SUPP
#include "utils/common.h"
#include "config.h"
#include "wpa_supplicant_i.h"
#endif /* CONFIG_WPA_SUPP */

#define SUPPLICANT_SHELL_MODULE "wpa_cli"

static struct {
	const struct shell *shell;

	union {
		struct {
			uint8_t connecting : 1;
			uint8_t disconnecting : 1;
			uint8_t _unused : 6;
		};
		uint8_t all;
	};
} context;

static uint32_t scan_result;

int cli_main(int argc, const char **argv);

extern struct wpa_supplicant *wpa_s_0;

struct wpa_ssid *ssid_0;

#define MAX_SSID_LEN 32


static void scan_result_cb(struct net_if *iface,
			   int status,
			   struct wifi_scan_result *entry)
{
	if (!iface) {
		return;
	}

	if (!entry) {
		if (status) {
			shell_fprintf(context.shell,
				      SHELL_WARNING,
				      "Scan request failed (%d)\n",
				      status);
		} else {
			shell_fprintf(context.shell,
				      SHELL_NORMAL,
				      "Scan request done\n");
		}

		return;
	}

	scan_result++;

	if (scan_result == 1U) {
		shell_fprintf(context.shell,
			      SHELL_NORMAL,
			      "\n%-4s | %-32s %-5s | %-4s | %-4s | %-5s\n", "Num", "SSID",
			      "(len)", "Chan", "RSSI", "Sec");
	}

	shell_fprintf(context.shell,
		      SHELL_NORMAL,
		      "%-4d | %-32s %-5u | %-4u | %-4d | %-5s\n",
		      scan_result,
		      entry->ssid,
		      entry->ssid_length,
		      entry->channel,
		      entry->rssi,
		      (entry->security == WIFI_SECURITY_TYPE_PSK ? "WPA/WPA2" : "Open"));
}


static int cmd_supplicant_scan(const struct shell *shell,
			       size_t argc,
			       const char *argv[])
{
	struct net_if *iface = net_if_get_default();
	const struct device *dev = net_if_get_device(iface);
	const struct wifi_nrf_dev_ops *dev_ops = dev->api;

	context.shell = shell;

	return dev_ops->off_api.disp_scan(dev,
					  scan_result_cb);
}


#ifdef CONFIG_WPA_SUPP
static int __wifi_args_to_params(size_t argc,
				 const char *argv[],
				 struct wifi_connect_req_params *params)
{
	char *endptr;
	int idx = 1;

	if (argc < 1) {
		return -EINVAL;
	}

	/* SSID */
	params->ssid = (char *)argv[0];
	params->ssid_length = strlen(params->ssid);

	/* PSK (optional) */
	if (idx < argc) {
		params->psk = (char *)argv[idx];
		params->psk_length = strlen(argv[idx]);
		params->security = WIFI_SECURITY_TYPE_PSK;
		idx++;

		if ((idx < argc) && (strlen(argv[idx]) <= 2)) {
			params->security = strtol(argv[idx], &endptr, 10);
		}
	} else {
		params->security = WIFI_SECURITY_TYPE_NONE;
	}

	return 0;
}


static int cmd_supplicant_connect(const struct shell *shell,
				  size_t argc,
				  const char *argv[])
{
	static struct wifi_connect_req_params cnx_params;
	struct wifi_connect_req_params *params;
	struct wpa_ssid *ssid = NULL;
	bool pmf = true;

	if (__wifi_args_to_params(argc - 1,
				  &argv[1],
				  &cnx_params)) {
		shell_help(shell);
		return -ENOEXEC;
	}

	params = &cnx_params;

	if (!wpa_s_0) {
		shell_fprintf(context.shell,
			      SHELL_ERROR,
			      "%s: wpa_supplicant is not initialized, dropping connect\n",
			      __func__);
		return -1;
	}

	ssid = wpa_supplicant_add_network(wpa_s_0);
	ssid->ssid = os_zalloc(sizeof(u8) * MAX_SSID_LEN);

	memcpy(ssid->ssid, params->ssid, params->ssid_length);
	ssid->ssid_len = params->ssid_length;
	ssid->disabled = 1;
	ssid->key_mgmt = WPA_KEY_MGMT_NONE;

	wpa_s_0->conf->filter_ssids = 1;
	wpa_s_0->conf->ap_scan = 1;

	if (params->psk) {
		// TODO: Extend enum wifi_security_type
		if (params->security == 3) {
			ssid->key_mgmt = WPA_KEY_MGMT_SAE;
			str_clear_free(ssid->sae_password);
			ssid->sae_password = dup_binstr(params->psk, params->psk_length);

			if (ssid->sae_password == NULL) {
				shell_fprintf(context.shell,
					      SHELL_ERROR,
					      "%s:Failed to copy sae_password\n",
					      __func__);
				return -1;
			}
		} else {
			if (params->security == 2)
				ssid->key_mgmt = WPA_KEY_MGMT_PSK_SHA256;
			else
				ssid->key_mgmt = WPA_KEY_MGMT_PSK;

			str_clear_free(ssid->passphrase);
			ssid->passphrase = dup_binstr(params->psk, params->psk_length);

			if (ssid->passphrase == NULL) {
				shell_fprintf(context.shell,
					      SHELL_ERROR,
					      "%s:Failed to copy passphrase\n",
					      __func__);
				return -1;
			}
		}

		wpa_config_update_psk(ssid);

		if (pmf)
			ssid->ieee80211w = 1;

	}

	wpa_supplicant_enable_network(wpa_s_0,
				      ssid);

	wpa_supplicant_select_network(wpa_s_0,
				      ssid);

	return 0;
}


static int cmd_supplicant(const struct shell *shell,
			  size_t argc,
			  const char *argv[])
{
	return cli_main(argc,
			argv);
}
#endif /* CONFIG_WPA_SUPP */


SHELL_STATIC_SUBCMD_SET_CREATE(
	wpa_cli_cmds,
	SHELL_CMD(scan,
		  NULL,
		  "Scan AP",
		  cmd_supplicant_scan),
#ifdef CONFIG_WPA_SUPP
	SHELL_CMD(connect,
		  NULL,
		  " \"<SSID>\""
		  "\nPassphrase (optional: valid only for secured SSIDs)>"
		  "\nKEY_MGMT (optional: 0-None, 1-WPA2, 2-WPA2-256, 3-WPA3)",
		  cmd_supplicant_connect),
	SHELL_CMD(add_network,
		  NULL,
		  "\"Add Network network id/number\"",
		  cmd_supplicant),
	SHELL_CMD(set_network,
		  NULL,
		  "\"Set Network params\"",
		  cmd_supplicant),
	SHELL_CMD(set,
		  NULL,
		  "\"Set Global params\"",
		  cmd_supplicant),
	SHELL_CMD(get,
		  NULL, "\"Get Global params\"",
		  cmd_supplicant),
	SHELL_CMD(enable_network,
		  NULL,
		  "\"Enable Network\"",
		  cmd_supplicant),
	SHELL_CMD(remove_network,
		  NULL,
		  "\"Remove Network\"",
		  cmd_supplicant),
	SHELL_CMD(get_network,
		  NULL,
		  "\"Get Network\"",
		  cmd_supplicant),
	SHELL_CMD(select_network,
		  NULL,
		  "\"Select Network which will be enabled; rest of the networks will be disabled\"",
		  cmd_supplicant),
	SHELL_CMD(disable_network,
		  NULL,
		  "\"\"",
		  cmd_supplicant),
	SHELL_CMD(disconnect,
		  NULL,
		  "\"\"",
		  cmd_supplicant),
	SHELL_CMD(reassociate,
		  NULL,
		  "\"\"",
		  cmd_supplicant),
	SHELL_CMD(status,
		  NULL,
		  "\"Get client status\"",
		  cmd_supplicant),
	SHELL_CMD(bssid,
		  NULL,
		  "\"Associate with this BSSID\"",
		  cmd_supplicant),
	SHELL_CMD(sta_autoconnect,
		  NULL,
		  "\"\"",
		  cmd_supplicant),
	SHELL_CMD(signal_poll,
		  NULL,
		  "\"\"",
		  cmd_supplicant),
#endif /* CONFIG_WPA_SUPP */
	SHELL_SUBCMD_SET_END);


SHELL_CMD_REGISTER(wpa_cli,
		   &wpa_cli_cmds,
		   "WPA supplicant commands",
		   NULL);


static int supplicant_shell_init(const struct device *unused)
{
	ARG_UNUSED(unused);

	context.shell = NULL;
	context.all = 0U;
	scan_result = 0U;

	return 0;
}


SYS_INIT(supplicant_shell_init,
	 APPLICATION,
	 CONFIG_KERNEL_INIT_PRIORITY_DEFAULT);
```

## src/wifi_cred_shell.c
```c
/*
 * Copyright (c) 2022 Nordic Semiconductor ASA
 *
 * SPDX-License-Identifier: LicenseRef-Nordic-5-Clause
 */

#include <zephyr/kernel.h>
#include <stdio.h>
#include <stdlib.h>
#include <zephyr/shell/shell.h>
#include <zephyr/sys/printk.h>
#include <zephyr/init.h>

#include <zephyr/net/net_if.h>
#include <zephyr/net/wifi_mgmt.h>
#include <zephyr/net/net_event.h>

#include <net/wifi_credentials.h>
#include <net/wifi_mgmt_ext.h>

#define MACSTR "%02hhx:%02hhx:%02hhx:%02hhx:%02hhx:%02hhx"

static void print_network_info_helper(void *cb_arg, const char *ssid, size_t ssid_len)
{
	int ret = 0;
	struct wifi_credentials_personal creds = { 0 };

	ret = wifi_credentials_get_by_ssid_personal_struct(ssid, ssid_len, &creds);
	if (ret) {
		printk("an error occurred when trying to load credentials for network \"%.*s\""
			". err: %d", ssid_len, ssid, ret);
		return;
	}
	printk("  network ssid: \"%.*s\", ssid_len: %d, type: %s",
		ssid_len, ssid, ssid_len,
		wifi_security_txt(creds.header.type));


	if (creds.header.type == WIFI_SECURITY_TYPE_PSK ||
	    creds.header.type == WIFI_SECURITY_TYPE_PSK_SHA256 ||
	    creds.header.type == WIFI_SECURITY_TYPE_SAE) {
		printk(", password: \"%.*s\", password_len: %d",
		       creds.password_len, creds.password, creds.password_len);
	}

	if (creds.header.flags & WIFI_CREDENTIALS_FLAG_BSSID) {
		printk(", bssid: " MACSTR,
		       creds.header.bssid[0], creds.header.bssid[1],
		       creds.header.bssid[2], creds.header.bssid[3],
		       creds.header.bssid[4], creds.header.bssid[5]);
	}

	if (creds.header.flags & WIFI_CREDENTIALS_FLAG_2_4GHz) {
		printk(", band: 2.4GHz");
	}

	if (creds.header.flags & WIFI_CREDENTIALS_FLAG_5GHz) {
		printk(", band: 5GHz");
	}

	if (creds.header.flags & WIFI_CREDENTIALS_FLAG_FAVORITE) {
		printk(", favorite");
	}
	printk("\n");
}

static enum wifi_security_type parse_sec_type(const char *s)
{
	if (strcmp("OPEN", s) == 0) {
		return WIFI_SECURITY_TYPE_NONE;
	}
	if (strcmp("WPA2-PSK", s) == 0) {
		return WIFI_SECURITY_TYPE_PSK;
	}
	if (strcmp("WPA2-PSK-SHA256", s) == 0) {
		return WIFI_SECURITY_TYPE_PSK_SHA256;
	}
	if (strcmp("WPA3-SAE", s) == 0) {
		return WIFI_SECURITY_TYPE_SAE;
	}
	return WIFI_SECURITY_TYPE_UNKNOWN;
}

static enum wifi_frequency_bands parse_band(const char *s)
{
	if (strcmp("2.4GHz", s) == 0) {
		return WIFI_FREQ_BAND_2_4_GHZ;
	}
	if (strcmp("5GHz", s) == 0) {
		return WIFI_FREQ_BAND_5_GHZ;
	}
	if (strcmp("6GHz", s) == 0) {
		return WIFI_FREQ_BAND_6_GHZ;
	}
	return WIFI_FREQ_BAND_UNKNOWN;
}

static int cmd_auto_connect(const struct shell *sh, size_t argc, char *argv[])
{
	struct net_if *iface = net_if_get_default();
	int rc = net_mgmt(NET_REQUEST_WIFI_CONNECT_STORED, iface, NULL, 0);

	if (rc) {
		printk("an error occurred when trying to auto-connect to a network. err: %d", rc);
	}
	return 0;
}

static int cmd_add_network(const struct shell *sh, size_t argc, char *argv[])
{
	int ret;

	if (argc < 3) {
		goto help;
	}

	struct wifi_credentials_personal creds = {
		.header.ssid_len = strlen(argv[1]),
		.header.type = parse_sec_type(argv[2]),
	};

	memcpy(creds.header.ssid, argv[1], creds.header.ssid_len);

	if (creds.header.type == WIFI_SECURITY_TYPE_UNKNOWN) {
		printk("cannot parse security type!\n");
		goto help;
	}

	size_t arg_idx = 3;

	if (creds.header.type == WIFI_SECURITY_TYPE_PSK ||
	    creds.header.type == WIFI_SECURITY_TYPE_PSK_SHA256 ||
	    creds.header.type == WIFI_SECURITY_TYPE_SAE) {
		/* parse passphrase */
		if (argc < 4) {
			printk("missing password\n");
			goto help;
		}
		creds.password_len = strlen(argv[3]);
		if (creds.password_len > CONFIG_WIFI_CREDENTIALS_SAE_PASSWORD_LENGTH ||
			(
				(creds.header.type == WIFI_SECURITY_TYPE_PSK ||
				 creds.header.type == WIFI_SECURITY_TYPE_PSK_SHA256) &&
				creds.password_len > WIFI_PSK_MAX_LEN
			)
		) {
			printk("psk is too long for this security type!\n");
			goto help;
		}
		memcpy(creds.password, argv[3], creds.password_len);
		++arg_idx;
	}

	if (arg_idx < argc) {
		/* look for bssid */
		ret = sscanf(argv[arg_idx], MACSTR,
			     &creds.header.bssid[0], &creds.header.bssid[1],
			     &creds.header.bssid[2], &creds.header.bssid[3],
			     &creds.header.bssid[4], &creds.header.bssid[5]);
		if (ret == 6) {
			creds.header.flags |= WIFI_CREDENTIALS_FLAG_BSSID;
			++arg_idx;
		}
	}

	if (arg_idx < argc) {
		/* look for band */
		enum wifi_frequency_bands band = parse_band(argv[arg_idx]);

		if (band == WIFI_FREQ_BAND_2_4_GHZ) {
			creds.header.flags |= WIFI_CREDENTIALS_FLAG_2_4GHz;
			++arg_idx;
		}
		if (band == WIFI_FREQ_BAND_5_GHZ) {
			creds.header.flags |= WIFI_CREDENTIALS_FLAG_5GHz;
			++arg_idx;
		}
	}

	if (arg_idx < argc) {
		/* look for favorite flag */
		if (strcmp("favorite", argv[arg_idx]) == 0) {
			creds.header.flags |= WIFI_CREDENTIALS_FLAG_FAVORITE;
			++arg_idx;
		}
	}

	if (arg_idx != argc) {
		for (size_t i = arg_idx; i < argc; ++i) {
			printk("unparsed arg: [%s]\n", argv[i]);
		}
	}

	return wifi_credentials_set_personal_struct(&creds);
help:
	printk("usage: wifi_cred add \"network name\""
		       " {OPEN, WPA2-PSK, WPA2-PSK-SHA256, WPA3-SAE}"
		       " [psk]"
		       " [bssid]"
		       " [{2.4GHz, 5GHz}]"
		       " [favorite]\n");
	return -EINVAL;
}

static int cmd_delete_network(const struct shell *sh, size_t argc, char *argv[])
{
	if (argc != 2) {
		printk("usage: wifi_cred delete \"network name\"\n");
		return -EINVAL;
	}
	printk("  deleting network ssid: \"%s\", ssid_len: %d\n", argv[1], strlen(argv[1]));
	return wifi_credentials_delete_by_ssid(argv[1], strlen(argv[1]));
}

static int cmd_list_networks(const struct shell *sh, size_t argc, char *argv[])
{
	wifi_credentials_for_each_ssid(print_network_info_helper, NULL);
	return 0;
}

SHELL_STATIC_SUBCMD_SET_CREATE(sub_wifi_cred,
	SHELL_CMD(auto_connect,	NULL, "Connect to any stored network.",	cmd_auto_connect),
	SHELL_CMD(add,		NULL, "Add network to storage.",	cmd_add_network),
	SHELL_CMD(delete,	NULL, "Delete network from storage.",	cmd_delete_network),
	SHELL_CMD(list,		NULL, "List stored networks.",		cmd_list_networks),
	SHELL_SUBCMD_SET_END
);

SHELL_CMD_REGISTER(wifi_cred, &sub_wifi_cred, "Wi-Fi Credentials commands", NULL);
```
